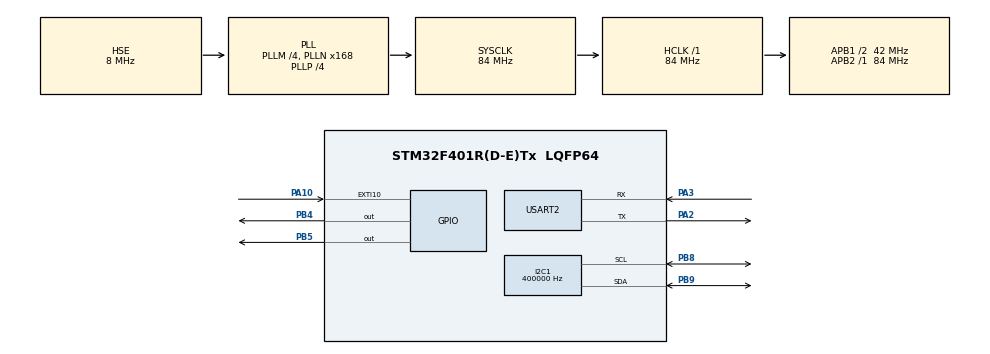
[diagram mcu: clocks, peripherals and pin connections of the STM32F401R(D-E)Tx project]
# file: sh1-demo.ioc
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FREERTOS.Tasks01=defaultTask,0,128,StartDefaultTask
I2C1.ClockSpeed=400000
I2C1.I2C_Mode=I2C_Fast
Mcu.Family=STM32F4
Mcu.Name=STM32F401R(D-E)Tx
Mcu.Package=LQFP64
NVIC.EXTI15_10_IRQn=true\:5\:0\:false
NVIC.I2C1_ER_IRQn=true\:5\:0\:false
NVIC.I2C1_EV_IRQn=true\:5\:0\:false
NVIC.PriorityGroup=NVIC_PRIORITYGROUP_4
NVIC.TIM1_UP_TIM10_IRQn=true\:0\:0\:false
NVIC.TimeBase=TIM1_UP_TIM10_IRQn
NVIC.TimeBaseIP=TIM1
NVIC.USART2_IRQn=true\:5\:0\:false
PA10.GPIO_ModeDefaultEXTI=GPIO_MODE_IT_FALLING
PA10.GPIO_PuPd=GPIO_PULLUP
PA10.Signal=GPXTI10
PA2.Mode=Asynchronous
PA2.Signal=USART2_TX
PA3.Mode=Asynchronous
PA3.Signal=USART2_RX
PB4.Signal=GPIO_Output
PB5.Signal=GPIO_Output
PB8.Mode=I2C
PB8.Signal=I2C1_SCL
PB9.Mode=I2C
PB9.Signal=I2C1_SDA
PC14-OSC32_IN.Mode=LSE-External-Oscillator
PC14-OSC32_IN.Signal=RCC_OSC32_IN
PC15-OSC32_OUT.Mode=LSE-External-Oscillator
PC15-OSC32_OUT.Signal=RCC_OSC32_OUT
PH0\ -\ OSC_IN.Mode=HSE-External-Oscillator
PH0\ -\ OSC_IN.Signal=RCC_OSC_IN
PH1\ -\ OSC_OUT.Mode=HSE-External-Oscillator
PH1\ -\ OSC_OUT.Signal=RCC_OSC_OUT
ProjectManager.HeapSize=0x400
ProjectManager.StackSize=0x200
ProjectManager.TargetToolchain=EWARM
RCC.48MHZClocksFreq_Value=48000000
RCC.AHBFreq_Value=84000000
RCC.APB1CLKDivider=RCC_HCLK_DIV2
RCC.APB1Freq_Value=42000000
RCC.APB1TimFreq_Value=84000000
RCC.APB2Freq_Value=84000000
RCC.APB2TimFreq_Value=84000000
RCC.CortexFreq_Value=84000000
RCC.HCLKFreq_Value=84000000
RCC.HSE_VALUE=8000000
RCC.HSI_VALUE=16000000
RCC.PLLM=4
RCC.PLLN=168
RCC.PLLP=RCC_PLLP_DIV4
RCC.PLLQ=7
RCC.PLLSourceVirtual=RCC_PLLSOURCE_HSE
RCC.SYSCLKFreq_VALUE=84000000
RCC.SYSCLKSource=RCC_SYSCLKSOURCE_PLLCLK
RCC.VCOOutputFreq_Value=336000000
TIM2.Period=0xFFFFFFFF
TIM2.Prescaler=84
VP_FREERTOS_VS_ENABLE.Mode=Enabled
VP_SYS_VS_tim1.Mode=TIM1
VP_TIM2_VS_ClockSourceINT.Mode=Internal
board=sh1-demo

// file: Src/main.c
/**
  ******************************************************************************
  * File Name          : main.c
  * Description        : Main program body
  ******************************************************************************
  *
  * COPYRIGHT(c) 2016 STMicroelectronics
  *
  * Redistribution and use in source and binary forms, with or without modification,
  * are permitted provided that the following conditions are met:
  *   1. Redistributions of source code must retain the above copyright notice,
  *      this list of conditions and the following disclaimer.
  *   2. Redistributions in binary form must reproduce the above copyright notice,
  *      this list of conditions and the following disclaimer in the documentation
  *      and/or other materials provided with the distribution.
  *   3. Neither the name of STMicroelectronics nor the names of its contributors
  *      may be used to endorse or promote products derived from this software
  *      without specific prior written permission.
  *
  * THIS SOFTWARE IS PROVIDED BY THE COPYRIGHT HOLDERS AND CONTRIBUTORS "AS IS"
  * AND ANY EXPRESS OR IMPLIED WARRANTIES, INCLUDING, BUT NOT LIMITED TO, THE
  * IMPLIED WARRANTIES OF MERCHANTABILITY AND FITNESS FOR A PARTICULAR PURPOSE ARE
  * DISCLAIMED. IN NO EVENT SHALL THE COPYRIGHT HOLDER OR CONTRIBUTORS BE LIABLE
  * FOR ANY DIRECT, INDIRECT, INCIDENTAL, SPECIAL, EXEMPLARY, OR CONSEQUENTIAL
  * DAMAGES (INCLUDING, BUT NOT LIMITED TO, PROCUREMENT OF SUBSTITUTE GOODS OR
  * SERVICES; LOSS OF USE, DATA, OR PROFITS; OR BUSINESS INTERRUPTION) HOWEVER
  * CAUSED AND ON ANY THEORY OF LIABILITY, WHETHER IN CONTRACT, STRICT LIABILITY,
  * OR TORT (INCLUDING NEGLIGENCE OR OTHERWISE) ARISING IN ANY WAY OUT OF THE USE
  * OF THIS SOFTWARE, EVEN IF ADVISED OF THE POSSIBILITY OF SUCH DAMAGE.
  *
  ******************************************************************************
  */
#include "stm32f4xx_hal.h"
#include "cmsis_os.h"

/* USER CODE BEGIN Includes */
#include "dbg.h"
#include "sh_bno_stm32f401.h"
#include "sensor_app.h"

/* USER CODE END Includes */

I2C_HandleTypeDef hi2c1;

TIM_HandleTypeDef htim2;

UART_HandleTypeDef huart2;

osThreadId defaultTaskHandle;

/* USER CODE BEGIN PV */
/* Private variables ---------------------------------------------------------*/

/* USER CODE END PV */

void SystemClock_Config(void);
static void MX_GPIO_Init(void);
static void MX_I2C1_Init(void);
static void MX_USART2_UART_Init(void);
static void MX_TIM2_Init(void);
void StartDefaultTask(void const * argument);

/* USER CODE BEGIN PFP */
/* Private function prototypes -----------------------------------------------*/

/* USER CODE END PFP */

/* USER CODE BEGIN 0 */

#define SENSOR_TASK_STACK 512
#define SENSOR_TASK_PRIO 0       // lowest priority

xTaskHandle sensorTaskHandle;

static void sensorThread(void * params)
{
  // Call into sensor_app.  (Never returns.)
  sensorTask();
}

/* USER CODE END 0 */

int main(void)
{

  /* MCU Configuration----------------------------------------------------------*/

  /* Reset of all peripherals, Initializes the Flash interface and the Systick. */
  HAL_Init();

  /* Configure the system clock */
  SystemClock_Config();

  /* Initialize all configured peripherals */
  MX_GPIO_Init();
  MX_I2C1_Init();
  MX_USART2_UART_Init();
  MX_TIM2_Init();

  /* USER CODE BEGIN 2 */
  dbgInit();
  bno_init(&hi2c1, &htim2);

  /* USER CODE END 2 */

  /* Create the thread(s) */
  /* definition and creation of defaultTask */
  osThreadDef(defaultTask, StartDefaultTask, osPriorityNormal, 0, 128);
  defaultTaskHandle = osThreadCreate(osThread(defaultTask), NULL);

  /* USER CODE BEGIN RTOS_THREADS */
  xTaskCreate(sensorThread, "SensorTask",
              SENSOR_TASK_STACK,
              0,
              SENSOR_TASK_PRIO, &sensorTaskHandle);

  /* USER CODE END RTOS_THREADS */

  /* Start scheduler */
  osKernelStart();

  /* We should never get here as control is now taken by the scheduler */

  /* Infinite loop */
  while (1)
  {

  }

}

/** System Clock Configuration
*/
void SystemClock_Config(void)
{

  RCC_OscInitTypeDef RCC_OscInitStruct;
  RCC_ClkInitTypeDef RCC_ClkInitStruct;

  __PWR_CLK_ENABLE();

  __HAL_PWR_VOLTAGESCALING_CONFIG(PWR_REGULATOR_VOLTAGE_SCALE2);

  RCC_OscInitStruct.OscillatorType = RCC_OSCILLATORTYPE_HSE;
  RCC_OscInitStruct.HSEState = RCC_HSE_ON;
  RCC_OscInitStruct.PLL.PLLState = RCC_PLL_ON;
  RCC_OscInitStruct.PLL.PLLSource = RCC_PLLSOURCE_HSE;
  RCC_OscInitStruct.PLL.PLLM = 4;
  RCC_OscInitStruct.PLL.PLLN = 168;
  RCC_OscInitStruct.PLL.PLLP = RCC_PLLP_DIV4;
  RCC_OscInitStruct.PLL.PLLQ = 7;
  HAL_RCC_OscConfig(&RCC_OscInitStruct);

  RCC_ClkInitStruct.ClockType = RCC_CLOCKTYPE_HCLK|RCC_CLOCKTYPE_SYSCLK
                              |RCC_CLOCKTYPE_PCLK1|RCC_CLOCKTYPE_PCLK2;
  RCC_ClkInitStruct.SYSCLKSource = RCC_SYSCLKSOURCE_PLLCLK;
  RCC_ClkInitStruct.AHBCLKDivider = RCC_SYSCLK_DIV1;
  RCC_ClkInitStruct.APB1CLKDivider = RCC_HCLK_DIV2;
  RCC_ClkInitStruct.APB2CLKDivider = RCC_HCLK_DIV1;
  HAL_RCC_ClockConfig(&RCC_ClkInitStruct, FLASH_LATENCY_2);

  HAL_SYSTICK_Config(HAL_RCC_GetHCLKFreq()/1000);

  HAL_SYSTICK_CLKSourceConfig(SYSTICK_CLKSOURCE_HCLK);

  /* SysTick_IRQn interrupt configuration */
  HAL_NVIC_SetPriority(SysTick_IRQn, 0, 0);
}

/* I2C1 init function */
void MX_I2C1_Init(void)
{

  hi2c1.Instance = I2C1;
  hi2c1.Init.ClockSpeed = 400000;
  hi2c1.Init.DutyCycle = I2C_DUTYCYCLE_2;
  hi2c1.Init.OwnAddress1 = 0;
  hi2c1.Init.AddressingMode = I2C_ADDRESSINGMODE_7BIT;
  hi2c1.Init.DualAddressMode = I2C_DUALADDRESS_DISABLED;
  hi2c1.Init.OwnAddress2 = 0;
  hi2c1.Init.GeneralCallMode = I2C_GENERALCALL_DISABLED;
  hi2c1.Init.NoStretchMode = I2C_NOSTRETCH_DISABLED;
  HAL_I2C_Init(&hi2c1);

}

/* TIM2 init function */
void MX_TIM2_Init(void)
{

  TIM_ClockConfigTypeDef sClockSourceConfig;
  TIM_MasterConfigTypeDef sMasterConfig;

  htim2.Instance = TIM2;
  htim2.Init.Prescaler = 84;
  htim2.Init.CounterMode = TIM_COUNTERMODE_UP;
  htim2.Init.Period = 0xFFFFFFFF;
  htim2.Init.ClockDivision = TIM_CLOCKDIVISION_DIV1;
  HAL_TIM_Base_Init(&htim2);

  sClockSourceConfig.ClockSource = TIM_CLOCKSOURCE_INTERNAL;
  HAL_TIM_ConfigClockSource(&htim2, &sClockSourceConfig);

  sMasterConfig.MasterOutputTrigger = TIM_TRGO_RESET;
  sMasterConfig.MasterSlaveMode = TIM_MASTERSLAVEMODE_DISABLE;
  HAL_TIMEx_MasterConfigSynchronization(&htim2, &sMasterConfig);

}

/* USART2 init function */
void MX_USART2_UART_Init(void)
{

  huart2.Instance = USART2;
  huart2.Init.BaudRate = 115200;
  huart2.Init.WordLength = UART_WORDLENGTH_8B;
  huart2.Init.StopBits = UART_STOPBITS_1;
  huart2.Init.Parity = UART_PARITY_NONE;
  huart2.Init.Mode = UART_MODE_TX_RX;
  huart2.Init.HwFlowCtl = UART_HWCONTROL_NONE;
  huart2.Init.OverSampling = UART_OVERSAMPLING_16;
  HAL_UART_Init(&huart2);

}

/** Configure pins as
        * Analog
        * Input
        * Output
        * EVENT_OUT
        * EXTI
*/
void MX_GPIO_Init(void)
{

  GPIO_InitTypeDef GPIO_InitStruct;

  /* GPIO Ports Clock Enable */
  __GPIOC_CLK_ENABLE();
  __GPIOH_CLK_ENABLE();
  __GPIOA_CLK_ENABLE();
  __GPIOB_CLK_ENABLE();

  /*Configure GPIO pin : PA10 */
  GPIO_InitStruct.Pin = GPIO_PIN_10;
  GPIO_InitStruct.Mode = GPIO_MODE_IT_FALLING;
  GPIO_InitStruct.Pull = GPIO_PULLUP;
  HAL_GPIO_Init(GPIOA, &GPIO_InitStruct);

  /*Configure GPIO pins : PB4 PB5 */
  GPIO_InitStruct.Pin = GPIO_PIN_4|GPIO_PIN_5;
  GPIO_InitStruct.Mode = GPIO_MODE_OUTPUT_PP;
  GPIO_InitStruct.Pull = GPIO_NOPULL;
  GPIO_InitStruct.Speed = GPIO_SPEED_LOW;
  HAL_GPIO_Init(GPIOB, &GPIO_InitStruct);

  /*Configure GPIO pin Output Level */
  HAL_GPIO_WritePin(GPIOB, GPIO_PIN_4|GPIO_PIN_5, GPIO_PIN_RESET);

  /* EXTI interrupt init*/
  HAL_NVIC_SetPriority(EXTI15_10_IRQn, 5, 0);
  HAL_NVIC_EnableIRQ(EXTI15_10_IRQn);

}

/* StartDefaultTask function */
void StartDefaultTask(void const * argument)
{

  for(;;)
  {
    osDelay(1);
  }
}

/************************ (C) COPYRIGHT STMicroelectronics *****END OF FILE****/
